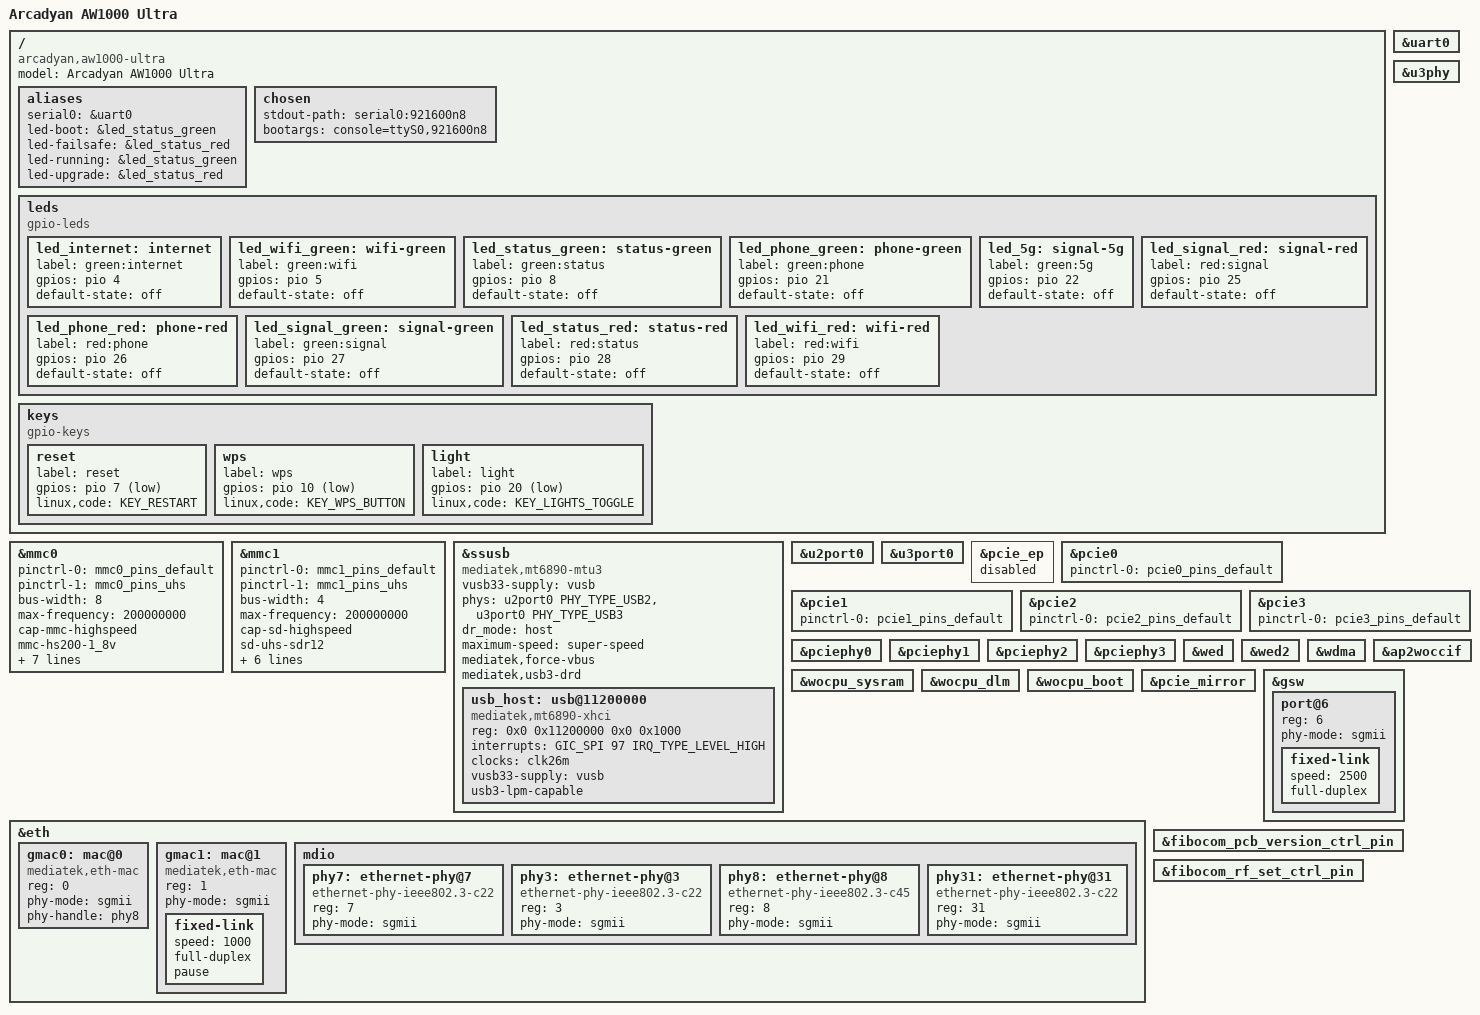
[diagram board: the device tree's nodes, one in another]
/dts-v1/;

#include "mt6890.dtsi"

#include <dt-bindings/gpio/gpio.h>
#include <dt-bindings/input/input.h>
#include <dt-bindings/interrupt-controller/arm-gic.h>
#include <dt-bindings/interrupt-controller/irq.h>
#include <dt-bindings/phy/phy.h>

/ {
	model = "Arcadyan AW1000 Ultra";
	compatible = "arcadyan,aw1000-ultra", "mediatek,mt6890";

	aliases {
		serial0 = &uart0;
		led-boot = &led_status_green;
		led-failsafe = &led_status_red;
		led-running = &led_status_green;
		led-upgrade = &led_status_red;
	};

	chosen {
		stdout-path = "serial0:921600n8";
		bootargs = "console=ttyS0,921600n8";
	};

	leds {
		compatible = "gpio-leds";

		led_internet: internet {
			label = "green:internet";
			gpios = <&pio 4 GPIO_ACTIVE_HIGH>;
			default-state = "off";
		};

		led_wifi_green: wifi-green {
			label = "green:wifi";
			gpios = <&pio 5 GPIO_ACTIVE_HIGH>;
			default-state = "off";
		};

		led_status_green: status-green {
			label = "green:status";
			gpios = <&pio 8 GPIO_ACTIVE_HIGH>;
			default-state = "off";
		};

		led_phone_green: phone-green {
			label = "green:phone";
			gpios = <&pio 21 GPIO_ACTIVE_HIGH>;
			default-state = "off";
		};

		led_5g: signal-5g {
			label = "green:5g";
			gpios = <&pio 22 GPIO_ACTIVE_HIGH>;
			default-state = "off";
		};

		led_signal_red: signal-red {
			label = "red:signal";
			gpios = <&pio 25 GPIO_ACTIVE_HIGH>;
			default-state = "off";
		};

		led_phone_red: phone-red {
			label = "red:phone";
			gpios = <&pio 26 GPIO_ACTIVE_HIGH>;
			default-state = "off";
		};

		led_signal_green: signal-green {
			label = "green:signal";
			gpios = <&pio 27 GPIO_ACTIVE_HIGH>;
			default-state = "off";
		};

		led_status_red: status-red {
			label = "red:status";
			gpios = <&pio 28 GPIO_ACTIVE_HIGH>;
			default-state = "off";
		};

		led_wifi_red: wifi-red {
			label = "red:wifi";
			gpios = <&pio 29 GPIO_ACTIVE_HIGH>;
			default-state = "off";
		};
	};

	keys {
		compatible = "gpio-keys";

		reset {
			label = "reset";
			gpios = <&pio 7 GPIO_ACTIVE_LOW>;
			linux,code = <KEY_RESTART>;
		};

		wps {
			label = "wps";
			gpios = <&pio 10 GPIO_ACTIVE_LOW>;
			linux,code = <KEY_WPS_BUTTON>;
		};

		light {
			label = "light";
			gpios = <&pio 20 GPIO_ACTIVE_LOW>;
			linux,code = <KEY_LIGHTS_TOGGLE>;
		};
	};
};

&uart0 {
	status = "okay";
};

&mmc0 {
	status = "okay";
	pinctrl-names = "default", "state_uhs";
	pinctrl-0 = <&mmc0_pins_default>;
	pinctrl-1 = <&mmc0_pins_uhs>;
	bus-width = <8>;
	max-frequency = <200000000>;
	cap-mmc-highspeed;
	mmc-hs200-1_8v;
	mmc-hs400-1_8v;
	cap-mmc-hw-reset;
	hs400-ds-delay = <0x12814>;
	supports-cqe;
	no-sdio;
	no-sd;
	non-removable;
};

&mmc1 {
	status = "okay";
	pinctrl-names = "default", "state_uhs";
	pinctrl-0 = <&mmc1_pins_default>;
	pinctrl-1 = <&mmc1_pins_uhs>;
	bus-width = <4>;
	max-frequency = <200000000>;
	cap-sd-highspeed;
	sd-uhs-sdr12;
	sd-uhs-sdr25;
	sd-uhs-sdr50;
	sd-uhs-sdr104;
	cd-gpios = <&pio 11 GPIO_ACTIVE_LOW>;
	no-mmc;
	no-sdio;
};

&ssusb {
	compatible = "mediatek,mt6890-mtu3", "mediatek,mtu3";
	status = "okay";
	reg-names = "mac", "ippc";
	vusb33-supply = <&vusb>;
	phys = <&u2port0 PHY_TYPE_USB2>, <&u3port0 PHY_TYPE_USB3>;
	dr_mode = "host";
	maximum-speed = "super-speed";
	mediatek,force-vbus;
	mediatek,usb3-drd;
	#address-cells = <2>;
	#size-cells = <2>;
	ranges;

	usb_host: usb@11200000 {
		compatible = "mediatek,mt6890-xhci", "mediatek,mtk-xhci";
		reg = <0x0 0x11200000 0x0 0x1000>;
		reg-names = "mac";
		interrupts = <GIC_SPI 97 IRQ_TYPE_LEVEL_HIGH>;
		clocks = <&clk26m>;
		clock-names = "sys_ck";
		vusb33-supply = <&vusb>;
		usb3-lpm-capable;
		status = "okay";
	};
};

&u3phy {
	status = "okay";
};

&u2port0 {
	status = "okay";
};

&u3port0 {
	status = "okay";
};

&pcie_ep {
	status = "disabled";
};

&pcie0 {
	status = "okay";
	pinctrl-names = "default";
	pinctrl-0 = <&pcie0_pins_default>;
};

&pcie1 {
	status = "okay";
	pinctrl-names = "default";
	pinctrl-0 = <&pcie1_pins_default>;
};

&pcie2 {
	status = "okay";
	pinctrl-names = "default";
	pinctrl-0 = <&pcie2_pins_default>;
};

&pcie3 {
	status = "okay";
	pinctrl-names = "default";
	pinctrl-0 = <&pcie3_pins_default>;
};

&pciephy0 {
	status = "okay";
};

&pciephy1 {
	status = "okay";
};

&pciephy2 {
	status = "okay";
};

&pciephy3 {
	status = "okay";
};

&wed {
	status = "okay";
};

&wed2 {
	status = "okay";
};

&wdma {
	status = "okay";
};

&ap2woccif {
	status = "okay";
};

&wocpu_sysram {
	status = "okay";
};

&wocpu_dlm {
	status = "okay";
};

&wocpu_boot {
	status = "okay";
};

&pcie_mirror {
	status = "okay";
};

&eth {
	status = "okay";

	gmac0: mac@0 {
		compatible = "mediatek,eth-mac";
		reg = <0>;
		phy-mode = "sgmii";
		phy-handle = <&phy8>;
	};

	gmac1: mac@1 {
		compatible = "mediatek,eth-mac";
		reg = <1>;
		phy-mode = "sgmii";

		fixed-link {
			speed = <1000>;
			full-duplex;
			pause;
		};
	};

	mdio {
		#address-cells = <1>;
		#size-cells = <0>;

		phy7: ethernet-phy@7 {
			reg = <7>;
			compatible = "ethernet-phy-ieee802.3-c22";
			phy-mode = "sgmii";
		};

		phy3: ethernet-phy@3 {
			reg = <3>;
			compatible = "ethernet-phy-ieee802.3-c22";
			phy-mode = "sgmii";
		};

		phy8: ethernet-phy@8 {
			reg = <8>;
			compatible = "ethernet-phy-ieee802.3-c45";
			phy-mode = "sgmii";
		};

		phy31: ethernet-phy@31 {
			reg = <31>;
			compatible = "ethernet-phy-ieee802.3-c22";
			phy-mode = "sgmii";
		};
	};
};

&gsw {
	status = "okay";

	port@6 {
		reg = <6>;
		phy-mode = "sgmii";

		fixed-link {
			speed = <2500>;
			full-duplex;
		};
	};
};

&fibocom_pcb_version_ctrl_pin {
	status = "okay";
};

&fibocom_rf_set_ctrl_pin {
	status = "okay";
};
